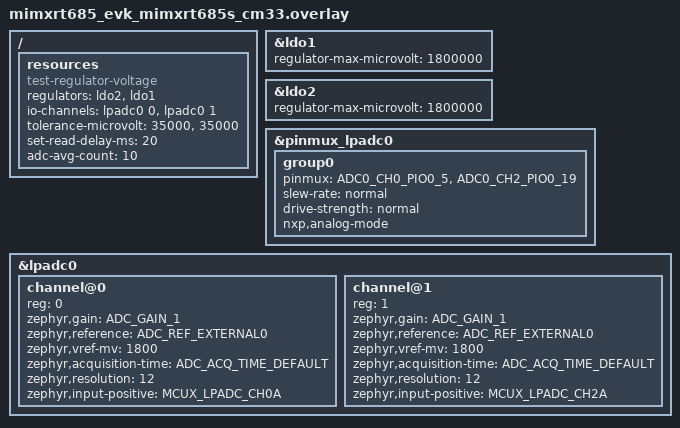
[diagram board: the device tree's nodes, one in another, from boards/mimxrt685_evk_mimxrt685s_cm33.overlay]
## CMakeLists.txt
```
# Copyright (c) 2022 Nordic Semiconductor ASA
# SPDX-License-Identifier: Apache-2.0

cmake_minimum_required(VERSION 3.20.0)
find_package(Zephyr REQUIRED HINTS $ENV{ZEPHYR_BASE})

project(regulator_voltage)

target_sources(app PRIVATE src/main.c)
```

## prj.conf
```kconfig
# Copyright (c) 2022 Nordic Semiconductor ASA
# SPDX-License-Identifier: Apache-2.0

CONFIG_ZTEST=y
CONFIG_ADC=y
CONFIG_REGULATOR=y
```

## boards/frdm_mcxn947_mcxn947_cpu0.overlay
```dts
/*
 * Copyright 2024 NXP
 * SPDX-License-Identifier: Apache-2.0
 */

#include <zephyr/dt-bindings/adc/adc.h>
#include <zephyr/dt-bindings/adc/mcux-lpadc.h>
#include <zephyr/dt-bindings/regulator/nxp_vref.h>

/* To do this test, connect LPADC0 channel 2A(J8 pin 28) to VREF_OUT (TP1) */

/ {
	resources: resources {
		compatible = "test-regulator-voltage";
		regulators = <&vref>;
		tolerance-microvolt = <10000>;
		set-read-delay-ms = <1>;
		adc-avg-count = <10>;
		io-channels = <&lpadc0 0>;
		min-microvolt = <1000000>;
		max-microvolt = <2100000>;
	};
};

&vref {
	regulator-initial-mode = <NXP_VREF_MODE_INTERNAL_REGULATOR>;
};

&lpadc0 {
	#address-cells = <1>;
	#size-cells = <0>;

	/* In this case, the LPADC reference source cannot be set to VREFO,
	 * switch the reference source to VDD_ANA.
	 */
	voltage-ref= <2>;

	channel@0 {
		reg = <0>;
		zephyr,gain = "ADC_GAIN_1";
		zephyr,reference = "ADC_REF_EXTERNAL0";
		zephyr,vref-mv = <3300>;
		zephyr,acquisition-time = <ADC_ACQ_TIME_DEFAULT>;
		zephyr,resolution = <12>;
		zephyr,input-positive = <MCUX_LPADC_CH2A>;
	};
};
```

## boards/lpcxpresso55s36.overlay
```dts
/*
 * Copyright 2023 NXP
 * SPDX-License-Identifier: Apache-2.0
 */

#include <zephyr/dt-bindings/adc/mcux-lpadc.h>
#include <zephyr/dt-bindings/regulator/nxp_vref.h>

/* To do this test, connect AN (J7-1) to VREF_OUT (J12-16) */

/ {
	resources: resources {
		compatible = "test-regulator-voltage";
		regulators = <&vref0>;
		tolerance-microvolt = <1000000>;
		set-read-delay-ms = <10>;
		adc-avg-count = <10>;
		io-channels = <&adc0 0>;
	};
};

&vref0 {
	regulator-initial-mode = <NXP_VREF_MODE_INTERNAL_REGULATOR>;
};

&adc0 {
	#address-cells = <1>;
	#size-cells = <0>;

	channel@0 {
		reg = <0>;
		zephyr,gain = "ADC_GAIN_1";
		zephyr,reference = "ADC_REF_EXTERNAL0";
		zephyr,vref-mv = <1800>;
		zephyr,acquisition-time = <ADC_ACQ_TIME_DEFAULT>;
		zephyr,resolution = <12>;
		zephyr,input-positive = <MCUX_LPADC_CH0A>;
	};
};
```

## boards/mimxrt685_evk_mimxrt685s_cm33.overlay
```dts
/*
 * Copyright 2022 NXP
 * SPDX-License-Identifier: Apache-2.0
 */

#include <zephyr/dt-bindings/adc/mcux-lpadc.h>

/* RT685 ADC only supports up to 1.8V,
 * so limit regulator voltage to this range.
 * Only test regulators we can safely change voltage to in RUN mode
 */
 &ldo1 {
	regulator-max-microvolt = <1800000>;
 };

 &ldo2 {
	regulator-max-microvolt = <1800000>;
 };

/* Override LPADC0 pinctrl settings */
&pinmux_lpadc0 {
	group0 {
		pinmux = <ADC0_CH0_PIO0_5>,
			<ADC0_CH2_PIO0_19>;
		slew-rate = "normal";
		drive-strength = "normal";
		nxp,analog-mode;
	};
};

/ {
	/* Note: make the following connections to run test on an RT685:
	 * J30.1-> TP15
	 * J30.3-> TP17
	 */
	resources: resources {
		compatible = "test-regulator-voltage";
		/* Note: LDO2 voltage range needs to be tested first
		 * to pass this test. It seems that when LDO2 is at the
		 * default voltage of 3.3V, LDO1 will not always deliver
		 * a voltage within given tolerance
		 */
		regulators = <&ldo2 &ldo1>;
		io-channels = <&lpadc0 0>, <&lpadc0 1>;
		tolerance-microvolt = <35000>, <35000>;
		set-read-delay-ms = <20>;
		adc-avg-count = <10>;
	};
};

&lpadc0 {
	#address-cells = <1>;
	#size-cells = <0>;

	channel@0 {
		reg = <0>;
		zephyr,gain = "ADC_GAIN_1";
		zephyr,reference = "ADC_REF_EXTERNAL0";
		zephyr,vref-mv = <1800>;
		zephyr,acquisition-time = <ADC_ACQ_TIME_DEFAULT>;
		zephyr,resolution = <12>;
		zephyr,input-positive = <MCUX_LPADC_CH0A>;
	};

	channel@1 {
		reg = <1>;
		zephyr,gain = "ADC_GAIN_1";
		zephyr,reference = "ADC_REF_EXTERNAL0";
		zephyr,vref-mv = <1800>;
		zephyr,acquisition-time = <ADC_ACQ_TIME_DEFAULT>;
		zephyr,resolution = <12>;
		zephyr,input-positive = <MCUX_LPADC_CH2A>;
	};
};
```

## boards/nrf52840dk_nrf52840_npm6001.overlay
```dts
/*
 * Copyright (c) 2022 Nordic Semiconductor ASA
 * SPDX-License-Identifier: Apache-2.0
 */

/ {
	/* NOTE: LDO0 change rate is low, so test may fail if its previous
	 * voltage was much higher than 1.8V, e.g. 3.3V. Wait a few seconds and
	 * re-run the test.
	 */
	resources: resources {
		compatible = "test-regulator-voltage";
		regulators = <&npm6001_ek_buck0 &npm6001_ek_buck1
			      &npm6001_ek_buck2 &npm6001_ek_buck3
			      &npm6001_ek_ldo0>;
		io-channels = <&adc 0>, <&adc 1>, <&adc 2>, <&adc 3>, <&adc 4>;
		tolerance-microvolt = <75000>, <25000>, <25000>, <75000>,
				      <75000>;
		set-read-delay-ms = <1>;
		adc-avg-count = <10>;
	};
};

&adc {
	#address-cells = <1>;
	#size-cells = <0>;

	channel@0 {
		reg = <0>;
		zephyr,gain = "ADC_GAIN_1_6";
		zephyr,reference = "ADC_REF_INTERNAL";
		zephyr,acquisition-time = <ADC_ACQ_TIME_DEFAULT>;
		zephyr,input-positive = <NRF_SAADC_AIN1>; /* P0.03 */
		zephyr,resolution = <12>;
	};

	channel@1 {
		reg = <1>;
		zephyr,gain = "ADC_GAIN_1_6";
		zephyr,reference = "ADC_REF_INTERNAL";
		zephyr,acquisition-time = <ADC_ACQ_TIME_DEFAULT>;
		zephyr,input-positive = <NRF_SAADC_AIN2>; /* P0.04 */
		zephyr,resolution = <12>;
	};

	channel@2 {
		reg = <2>;
		zephyr,gain = "ADC_GAIN_1_6";
		zephyr,reference = "ADC_REF_INTERNAL";
		zephyr,acquisition-time = <ADC_ACQ_TIME_DEFAULT>;
		zephyr,input-positive = <NRF_SAADC_AIN3>; /* P0.05 */
		zephyr,resolution = <12>;
	};

	channel@3 {
		reg = <3>;
		zephyr,gain = "ADC_GAIN_1_6";
		zephyr,reference = "ADC_REF_INTERNAL";
		zephyr,acquisition-time = <ADC_ACQ_TIME_DEFAULT>;
		zephyr,input-positive = <NRF_SAADC_AIN4>; /* P0.28 */
		zephyr,resolution = <12>;
	};

	channel@4 {
		reg = <4>;
		zephyr,gain = "ADC_GAIN_1_6";
		zephyr,reference = "ADC_REF_INTERNAL";
		zephyr,acquisition-time = <ADC_ACQ_TIME_DEFAULT>;
		zephyr,input-positive = <NRF_SAADC_AIN5>; /* P0.29 */
		zephyr,resolution = <12>;
	};
};
```

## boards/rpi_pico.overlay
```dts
/*
 * Copyright (c) 2023 TOKITA Hiroshi <tokita.hiroshi@fujitsu.com>
 * SPDX-License-Identifier: Apache-2.0
 */

/ {
	/* NOTE: It is necessary to connect VREG_OUT to the ADC to perform the test.
	 * But the rpi_pico board and most boards that use the rp2040, VREG_OUT and
	 * DVDD are directly connected, and no available exposed trace on the board.
	 *
	 * In the rpi_pico board, a short, thick, diagonal wiring pattern near the 3x3
	 * thermal via connect to VREG_OUT. (Around between C and E of CE mark of silk print.)
	 * Scraping the resist on there and soldering wire to make it able to measure by ADC.
	 */
	resources: resources {
		compatible = "test-regulator-voltage";
		regulators = <&vreg>;
		io-channels = <&adc 0>;
		tolerance-microvolt = <50000>;
		set-read-delay-ms = <10>;
		adc-avg-count = <10>;
		min-microvolt = <850000>;
	};
};

&vreg {
	raspberrypi,brown-out-threshold = <473000>;
};

&adc {
	#address-cells = <1>;
	#size-cells = <0>;

	channel@0 {
		reg = <0>;
		zephyr,gain = "ADC_GAIN_1";
		zephyr,reference = "ADC_REF_INTERNAL";
		zephyr,acquisition-time = <ADC_ACQ_TIME_DEFAULT>;
		zephyr,resolution = <12>;
	};
};
```

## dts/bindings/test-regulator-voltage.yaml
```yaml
# Copyright 2022 Nordic Semiconductor ASA
# SPDX-License-Identifier: Apache-2.0

description: |
    This binding provides resources required to build and run the
    tests/drivers/regulator/voltage test in Zephyr.

compatible: "test-regulator-voltage"

properties:
  regulators:
    type: phandles
    required: true
    description: |
      Regulators to be tested. Each entry must have a matching ADC entry in
      io-channels.

  io-channels:
    type: phandle-array
    required: true
    description: |
      ADC channels to be used. Each entry must have a matching entry in
      regulators.

  tolerance-microvolt:
    type: array
    required: true
    description: |
      Tolerance (+/-) when reading configured voltages using ADC. This should
      be set at most to the regulator resolution. Some noisy regulators may
      require more, though. Each entry must have a matching entry in
      regulators.

  adc-avg-count:
    type: int
    default: 1
    description: |
      Number of ADC readings to average. Defaults to 1 (no average).

  set-read-delay-ms:
    type: int
    default: 0
    description: |
      Delay between voltage set and ADC read. Defaults to 0 (no delay).

  min-microvolt:
    type: int
    default: -2147483648
    description: |
      Specifies the minimum voltage at which the test will run, in microvolts.
      Used to filter out ranges that cannot be tested correctly in the configuration.

  max-microvolt:
    type: int
    default: 2147483647
    description: |
      Specifies the maximum voltage at which the test will run, in microvolts.
      Used to filter out ranges that cannot be tested correctly in the configuration.
```

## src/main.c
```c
/*
 * Copyright (c) 2022 Nordic Semiconductor ASA
 * SPDX-License-Identifier: Apache-2.0
 */

#include <zephyr/device.h>
#include <zephyr/devicetree.h>
#include <zephyr/drivers/adc.h>
#include <zephyr/drivers/regulator.h>
#include <zephyr/sys/util.h>
#include <zephyr/ztest.h>

#define REG_INIT(node_id, prop, idx) \
	DEVICE_DT_GET(DT_PHANDLE_BY_IDX(node_id, prop, idx)),

#define ADC_INIT(node_id, prop, idx) \
	ADC_DT_SPEC_GET_BY_IDX(node_id, idx),

static const struct device *regs[] = {
	DT_FOREACH_PROP_ELEM(DT_NODELABEL(resources), regulators, REG_INIT)
};

static const struct adc_dt_spec adc_chs[] = {
	DT_FOREACH_PROP_ELEM(DT_NODELABEL(resources), io_channels, ADC_INIT)
};

static const int32_t tols[] =
	DT_PROP(DT_NODELABEL(resources), tolerance_microvolt);

static const unsigned int adc_avg_count = DT_PROP(DT_NODELABEL(resources),
						  adc_avg_count);
static const int32_t set_read_delay_ms = DT_PROP(DT_NODELABEL(resources),
						 set_read_delay_ms);

static const int32_t min_microvolt = DT_PROP(DT_NODELABEL(resources), min_microvolt);
static const int32_t max_microvolt = DT_PROP(DT_NODELABEL(resources), max_microvolt);

ZTEST(regulator_voltage, test_output_voltage)
{
	int16_t buf;
	struct adc_sequence sequence = {
		.buffer = &buf,
		.buffer_size = sizeof(buf),
	};

	for (size_t i = 0U; i < ARRAY_SIZE(regs); i++) {
		int ret;
		unsigned int volt_cnt;
		int32_t volt_uv;

		ret = adc_sequence_init_dt(&adc_chs[i], &sequence);
		zassert_equal(ret, 0);

		volt_cnt = regulator_count_voltages(regs[i]);
		zassume_not_equal(volt_cnt, 0U);

		TC_PRINT("Testing %s, %u voltage/s (tolerance: %d uV)\n",
			 regs[i]->name, volt_cnt, tols[i]);

		ret = regulator_enable(regs[i]);
		zassert_equal(ret, 0);

		for (unsigned int j = 0U; j < volt_cnt; j++) {
			int32_t val_mv = 0;

			(void)regulator_list_voltage(regs[i], j, &volt_uv);
			/* Check if voltage is outside user constraints */
			if (!regulator_is_supported_voltage(regs[i],
				volt_uv, volt_uv)) {
				continue;
			}

			if ((volt_uv < min_microvolt) || (volt_uv > max_microvolt)) {
				TC_PRINT("Skip: %d uV\n", volt_uv);
				continue;
			}

			ret = regulator_set_voltage(regs[i], volt_uv, volt_uv);
			zassert_equal(ret, 0);

			if (set_read_delay_ms > 0) {
				k_msleep(set_read_delay_ms);
			}

			for (unsigned int k = 0U; k < adc_avg_count; k++) {
				ret = adc_read_dt(&adc_chs[i], &sequence);
				zassert_equal(ret, 0);

				val_mv += buf;
			}

			val_mv /= (int32_t)adc_avg_count;

			ret = adc_raw_to_millivolts_dt(&adc_chs[i], &val_mv);
			zassert_equal(ret, 0);

			TC_PRINT("Set: %d, read: %d uV\n", volt_uv,
				 val_mv * 1000);

			zassert_between_inclusive(val_mv * 1000,
						  volt_uv - tols[i],
						  volt_uv + tols[i]);
		}

		ret = regulator_disable(regs[i]);
		zassert_equal(ret, 0);
	}
}

void *setup(void)
{
	zassert_equal(ARRAY_SIZE(regs), ARRAY_SIZE(adc_chs));
	zassert_equal(ARRAY_SIZE(regs), ARRAY_SIZE(tols));

	for (size_t i = 0U; i < ARRAY_SIZE(regs); i++) {
		zassert_true(device_is_ready(regs[i]));
		zassert_true(adc_is_ready_dt(&adc_chs[i]));
		zassert_equal(adc_channel_setup_dt(&adc_chs[i]), 0);
	}

	return NULL;
}

ZTEST_SUITE(regulator_voltage, NULL, setup, NULL, NULL, NULL);
```
